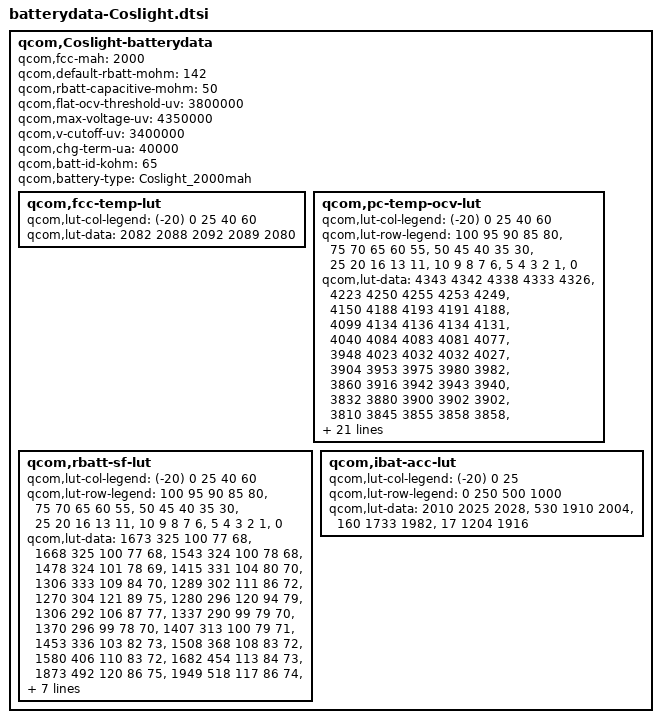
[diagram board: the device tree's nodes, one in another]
/* Copyright (c) 2013-2014  The Linux Foundation. All rights reserved.
 *
 * This program is free software; you can redistribute it and/or modify
 * it under the terms of the GNU General Public License version 2 and
 * only version 2 as published by the Free Software Foundation.
 *
 * This program is distributed in the hope that it will be useful,
 * but WITHOUT ANY WARRANTY; without even the implied warranty of
 * MERCHANTABILITY or FITNESS FOR A PARTICULAR PURPOSE.  See the
 * GNU General Public License for more details.
 */


qcom,Coslight-batterydata {


	qcom,fcc-mah = <2000>;
	qcom,default-rbatt-mohm = <142>;
	qcom,rbatt-capacitive-mohm = <50>;
	qcom,flat-ocv-threshold-uv = <3800000>;
	qcom,max-voltage-uv = <4350000>;
	qcom,v-cutoff-uv = <3400000>;
	qcom,chg-term-ua = <40000>;
	qcom,batt-id-kohm = <65>;
	qcom,battery-type = "Coslight_2000mah";

	qcom,fcc-temp-lut {
		qcom,lut-col-legend = <(-20) 0 25 40 60>;
		qcom,lut-data = <2082 2088 2092 2089 2080>;  
	};

	qcom,pc-temp-ocv-lut {
		qcom,lut-col-legend = <(-20) 0 25 40 60>;
		qcom,lut-row-legend = <100 95 90 85 80>,
				<75 70 65 60 55>,
				<50 45 40 35 30>,
				<25 20 16 13 11>,
				<10 9 8 7 6>,
				<5 4 3 2 1>,
				<0>;
		qcom,lut-data = <4343 4342 4338 4333 4326>, 
				<4223 4250 4255 4253 4249>, 
				<4150 4188 4193 4191 4188>, 
				<4099 4134 4136 4134 4131>, 
				<4040 4084 4083 4081 4077>, 
				<3948 4023 4032 4032 4027>, 
				<3904 3953 3975 3980 3982>, 
				<3860 3916 3942 3943 3940>, 
				<3832 3880 3900 3902 3902>, 
				<3810 3845 3855 3858 3858>, 
				<3792 3816 3822 3822 3822>, 
				<3774 3796 3800 3800 3800>, 
				<3755 3782 3785 3784 3782>, 
				<3736 3773 3776 3774 3770>, 
				<3716 3763 3769 3764 3756>, 
				<3696 3749 3757 3749 3736>, 
				<3670 3730 3739 3730 3718>, 
				<3646 3704 3716 3710 3698>, 
				<3622 3683 3692 3688 3677>, 
				<3600 3664 3676 3673 3664>, 
				<3588 3653 3666 3666 3660>, 
				<3572 3637 3650 3652 3650>, 
				<3554 3617 3628 3630 3633>, 
				<3531 3592 3600 3602 3606>, 
				<3504 3562 3568 3572 3576>, 
				<3470 3523 3531 3533 3534>, 
				<3430 3472 3478 3479 3480>, 
				<3376 3406 3409 3410 3412>, 
				<3305 3318 3322 3324 3328>, 
				<3198 3192 3202 3208 3214>, 
				<3000 3000 3025 3014 3000>;

	};

	qcom,rbatt-sf-lut {
		qcom,lut-col-legend = <(-20) 0 25 40 60>;
		qcom,lut-row-legend = <100 95 90 85 80>,
				<75 70 65 60 55>,
				<50 45 40 35 30>,
				<25 20 16 13 11>,
				<10 9 8 7 6>,
				<5 4 3 2 1>,
				<0>;
		qcom,lut-data = <1673 325 100 77 68>, 
				<1668 325 100 77 68>, 
				<1543 324 100 78 68>, 
				<1478 324 101 78 69>, 
				<1415 331 104 80 70>, 
				<1306 333 109 84 70>, 
				<1289 302 111 86 72>, 
				<1270 304 121 89 75>, 
				<1280 296 120 94 79>, 
				<1306 292 106 87 77>, 
				<1337 290 99 79 70>, 
				<1370 296 99 78 70>, 
				<1407 313 100 79 71>, 
				<1453 336 103 82 73>, 
				<1508 368 108 83 72>, 
				<1580 406 110 83 72>, 
				<1682 454 113 84 73>, 
				<1873 492 120 86 75>, 
				<1949 518 117 86 74>, 
				<2297 569 128 89 75>, 
				<2537 601 139 92 77>, 
				<2812 631 153 95 78>, 
				<3173 664 166 101 80>, 
				<3689 699 175 106 82>, 
				<4358 740 181 109 84>, 
				<5290 794 187 112 84>, 
				<6713 872 193 111 85>, 
				<9008 1008 207 115 87>, 
				<12949 1375 231 126 94>, 
				<21207 2317 285 158 114>, 
				<42414 4634 570 315 228>;

	};


	qcom,ibat-acc-lut {
		qcom,lut-col-legend = <(-20) 0 25>;
		qcom,lut-row-legend = <0 250 500 1000>;
		qcom,lut-data = <2010 2025 2028>,
				<530 1910 2004>,
				<160 1733 1982>,
				<17 1204 1916>;						
	};


};
